# YTM32B1MD2 register map
Vendor: YTMicro; File version: 1.0
CPU: CM33 r0p4, little endian, MPU, FPU, 2 interrupt priority bits
Registers are 32-bit, read-write, reset 0x0 unless marked. A register's access mark holds for its fields unless they carry their own. Offsets are from the block's base; [hi:lo] are bit positions; {n}, {i} and the like mark numbered series; 'fields as' and 'values as' point back to an identical list.

## DMA0 — Direct Memory Access
Base 0x40008000; register names take the prefix DMA0_
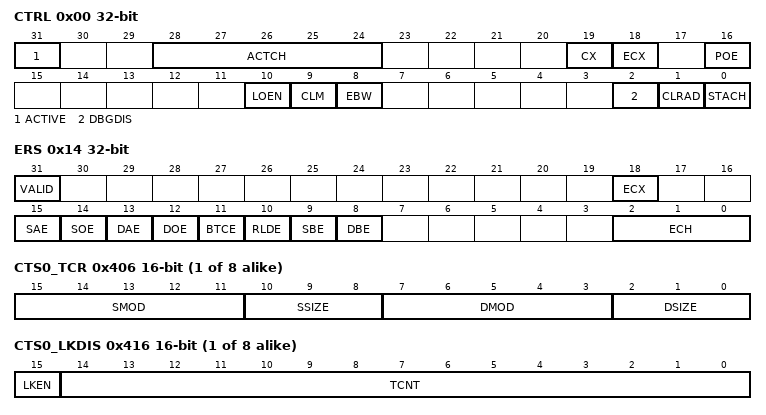
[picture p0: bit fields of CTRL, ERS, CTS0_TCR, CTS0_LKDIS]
0x00 CTRL
  [31] ACTIVE ro — Shows current DMA active state
    0=DMA is idle; 1=DMA is active
  [28:24] ACTCH ro — Shows current DMA active channel. ewline This field only valid when DMA active, when DMA is idle ACTCH = 0
  [19] CX — Setting this bit will terminate DMA data transfer after DMA finished current write operation. ewline This bit is cleared by hardware after DMA data transfer terminated.
    0=DMA in normal operation; 1=Cancel DMA data transfer
  [18] ECX — Setting this bit will terminate DMA data transfer after DMA finished current write operation and set error flag. ewline This bit is cleared by hardware after DMA data transfer terminated.
    0=DMA in normal operation; 1=Cancel DMA data transfer and set error flag
  [16] POE — Pause DMA following channel transfer when any DMA error happened
    0=DMA in normal operation; 1=DMA transfer is paused as DMA error happens, software need to handle the error and clear this bit to continue following data transfer
  [10] LOEN — Enable loop offset adjustment, this bit will affect all DMA channels transfer loop setting.
    0=DMA loop offset is disabled; 1=DMA loop is enabled and CTS[BCNT] split into SLOEN, DLOEN, OFFSET and BCNT
  [9] CLM — ote{Only set this bit when more than one DMA channel enabled}
    0=DMA will serve other channel even if DMA channel linking to itself; 1=DMA will restart current channel transfer if DMA channel linking to itself
  [8] EBW — When buffered writes are enabled, all writes except for the last write sequence of the minor loop are signaled by the DMA as bufferable.
    0=Buffered writes on system bus disable. Buffered writes on system bus disabled; 1=Buffered writes on system bus enabled. Bufferable write signal asserted on all system bus writes except during last write sequence
  [2] DBGDIS — Setting this bit will pause DMA transfer when CPU is halted
    0=DMA in normal operation; 1=DMA transfer is paused when CPU is halted
  [1] CLRAD wo — Setting this bit will clear all DMA channel done flags
    0=No effects; 1=Clear all DMA channel done flags
  [0] STACH wo — Setting this bit will start all DMA channel
    0=No effects; 1=Start all DMA channels
0x04 CHTLDIF
  [7:0] CH — CH[n] is channel n trigger loop done interrupt flag, write 1 to clear this bit.
0x08 CHTLHDIF
  [7:0] CH — CH[n] is channel n trigger loop half done interrupt flag, write 1 to clear this bit.
0x0C CHEIF
  [7:0] CH — CH[n] is channel n error interrupt flag
0x10 CHEIE
  [7:0] CH — CH[n] is channel n error interrupt enable control bit
0x14 ERS
  [31] VALID ro — All DMA channel configurations are valid.
    0=No DMA error happens; 1=DMA error happens on at least one DMA channel
  [18] ECX ro
    0=No DMA error happens; 1=DMA error happens because and data transfer error happened
  [15] SAE ro — DMA channel source address configuration error
    0=No DMA source address error happens; 1=At least one DMA channel has source address configuration error. ewline Check CTSn_SADDR and CTSn_TCR configuration.
  [14] SOE ro — DMA source offset configuration error
    0=No DMA source offset error happens; 1=At least one DMA channel has source offset configuration error. ewline Check CTSn_SOFF and CTSn_TCR configuration.
  [13] DAE ro — DMA channel destination address configuration error
    0=No DMA destination address error happens; 1=At least one DMA channel has destination address configuration error. ewline Check CTSn_DADDR and CTSn_TCR configuration.
  [12] DOE ro — DMA channel destination offset configuration error
    0=No DMA destination offset error happens; 1=At least one DMA channel has destination offset configuration error. ewline Check CTSn_DOFF and CTSn_TCR configuration.
  [11] BTCE ro — Byte count or trigger count configuration not match DMA transfer size
    0=No DMA byte/trigger count error happens; 1=At least one DMA channel has byte/trigger count configuration error. ewline Check CTSn_BCNT, CTSn_TCNT, CTSn_TCR configuration. ewline
  [10] RLDE ro — Target reload address is not aligned with 32 bytes
    0=No DMA ram reload error happens; 1=At least one DMA channel has ram reload configuration error. ewline Check CTSn_RLDADDR(should be 32 byte align) ewline
  [9] SBE ro — Bus error happened when DMA reading data from source address.
    0=No DMA source bus error happens; 1=At least one DMA channel has source bus data access error. System bus error happens when DMA reading data from source address.
  [8] DBE ro — Bus error happened when DMA writing data to destination address.
    0=No DMA destination bus error happens; 1=At least one DMA channel has destination bus data access error. System bus error happened when dma write data to destination address.
  [2:0] ECH ro — Channel index of error captured ote{This field is valid only when DMA error happened.}
0x18 REQEN
  [7:0] CH — Hardware DMA request for channel [n] enable control bit, one bit for one channel.
0x1C REQS
  [7:0] CH ro — Hardware DMA request status for channel [n], one bit for one channel.
0x20 START
  [7:0] CH — Start DMA channel [n], one bit for one channel.
0x24 DONE
  [7:0] CH — Trigger loop done for channel [n], one bit for one channel.
{0x40+i} CHMUX{i} 8-bit (i=0..7)
  [5:0] CH — DMA hardware request input index, please refer to \hyperref[DMA-Channel-Mux-Table]{DMA MUX table} for MUX detail
0x60 REQSET
  [7:0] CH wo — Set the DMA request enable for the corresponding channel.
0x64 REQCLR
  [7:0] CH wo — Set the DMA request disable for the corresponding channel.
{0x400+0x20*i} CTS{i}_SADDR (i=0..7)
  [31:0] SADDR — Source address of DMA transfer.
{0x404+0x20*i} CTS{i}_SOFF 16-bit (i=0..7)
  [15:0] SOFF — Source address will add offset value(support signed-short type) after each DMA transfer size completed.
{0x406+0x20*i} CTS{i}_TCR 16-bit (i=0..7)
  [15:11] SMOD — Source address will add offset value(support signed-short type) and modulo SMOD after each DMA transfer size completed.
  [10:8] SSIZE — Source data transfer size is DMA access source data width.
    0=8-bit; 1=16-bit; 2=32-bit; 4=16 bytes burst; 5=32 bytes burst
  [7:3] DMOD — Destination address will add offset value(support signed-short type) and modulo SMOD after each DMA transfer size completed.
  [2:0] DSIZE — Destination data transfer size is DMA write destination data width.
    values as SSIZE
{0x408+0x20*i} CTS{i}_BCNT (i=0..7) — Transfer loop byte count is the number of bytes to be transferred in each trigger loop.
  [31:0] BCNT — Valid for CTRL[LOEN] = 0, Transfer loop byte count is the number of bytes to be transferred in each trigger loop.
{0x40C+0x20*i} CTS{i}_STO (i=0..7)
  [31:0] STLOFF — Source address will add offset value(support signed-short type) after DMA channel trigger loop completed.
{0x410+0x20*i} CTS{i}_DADDR (i=0..7)
  [31:0] DADDR — Destination address where DMA will transfer data to.
{0x414+0x20*i} CTS{i}_DOFF 16-bit (i=0..7)
  [15:0] DOFF — Destination address will add offset value(support signed-short type) after each DMA transfer (write operation with DSIZE) completed.
{0x416+0x20*i} CTS{i}_LKDIS 16-bit (i=0..7)
  [15] LKEN — Enable channel to channel linking after DMA one trigger loop complete. This bit should be 0 when channel to channel link mode is disabled.
    0=Channel to channel linking is disabled; 1=Channel to channel linking is enabled, refer LKEN for register information
  [14:0] TCNT — Trigger counter decrease 1 for every DMA trigger
{0x418+0x20*i} CTS{i}_DTO (i=0..7)
  [31:0] OFFSET — Destination address will add offset value(support signed-short type) after DMA channel trigger loop completed (trigger count reaches zero).
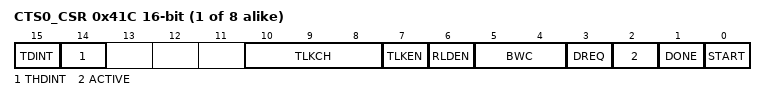
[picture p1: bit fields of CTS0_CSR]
{0x41C+0x20*i} CTS{i}_CSR 16-bit (i=0..7)
  [15] TDINT — Enable an interrupt when channel all trigger loop done
    0=Channel trigger loop done interrupt not enabled; 1=Channel trigger loop done interrupt enabled
  [14] THDINT — Enable an interrupt when half trigger loop done
    0=Channel trigger loop half done interrupt not enabled; 1=Channel trigger loop half done interrupt enabled
  [10:8] TLKCH — Setting this bit will let current DMA channel trigger linked DMA channel after current DMA channel all trigger loop completed
  [7] TLKEN — Enable channel to channel linking on all trigger loop complete
    0=Channel trigger loop done link not enabled; 1=Channel trigger loop done link enabled
  [6] RLDEN — Setting this bit will current DMA channel load new configurations from system memory map after trigger loop completed
    0=Channel trigger loop done ram reload not enabled; 1=Channel trigger loop done ram reload enabled
  [5:4] BWC — Bandwidth control let DMA insert wait cycles between each R/W operation, this allows user to balance bus loadings. ote{If DMA need to transfer large amount of data, it is recommended to set BWC to 2. otherwise, CPU may need to wait DMA transfer for bus access.}
    0=DMA transfer data continuous; 2=DMA engine wait 4 cycles after each R/W; 3=DMA engine wait 8 cycles after each R/W
  [3] DREQ — Setting this bit will let DMA clear channel hardware request enable bit after trigger loop completed (TCNT decrease to zero).
    0=Channel trigger loop done won't clear channel hardware request enable bit, DMA will continue serve hardware request until even if TCNT already decrease down to zero; 1=Channel trigger loop done will clear channel hardware request enable bit
  [2] ACTIVE ro
    0=DMA channel is not active; 1=DMA channel is active
  [1] DONE
    0=DMA channel trigger loop not done; 1=DMA channel trigger loop done
  [0] START
    0=DMA channel is not started; 1=DMA channel is started and waiting for trigger or active
{0x41E+0x20*i} CTS{i}_TCNTRV 16-bit (i=0..7)
  [15:0] RV — DMA will reload channel's TCNT with TCNTRV after DMA TCNT decreased to zero. This register share same register map with TCNT register.
